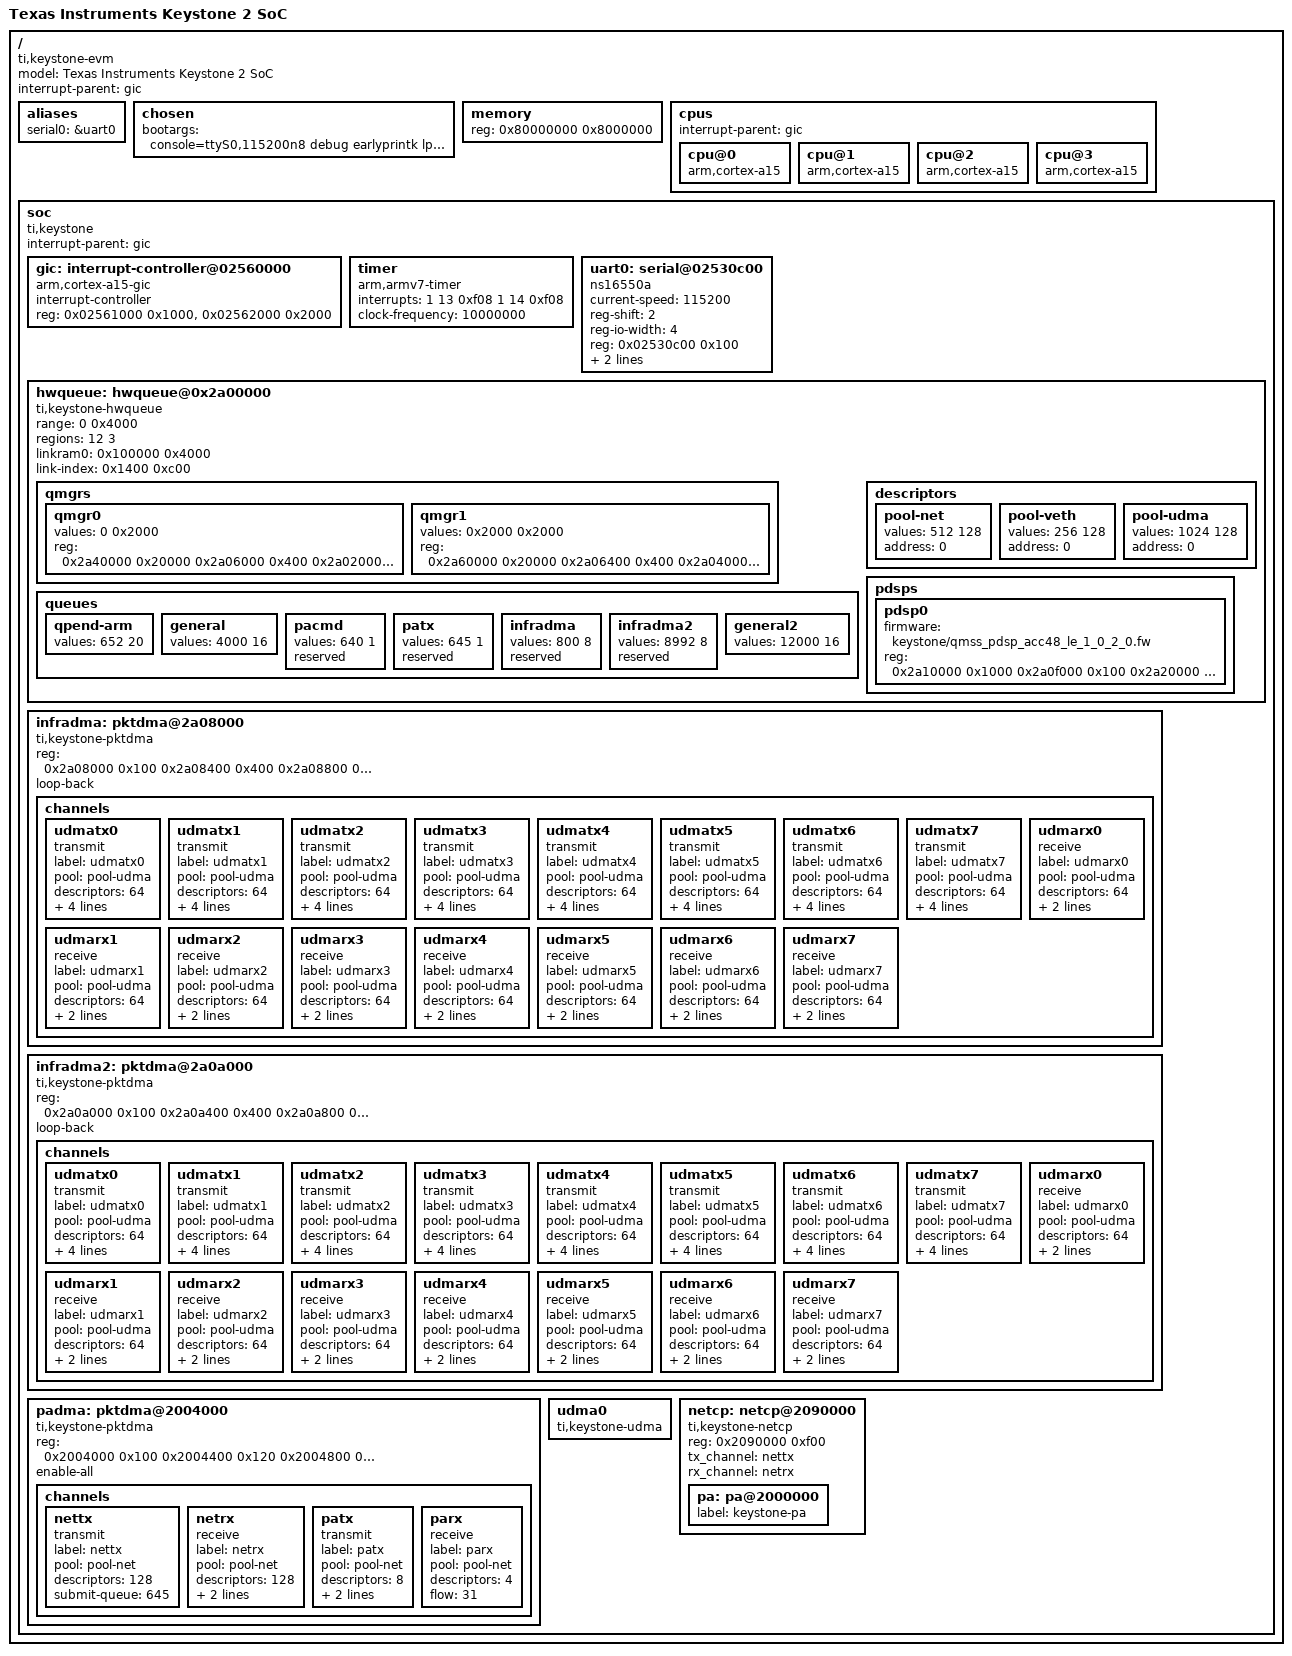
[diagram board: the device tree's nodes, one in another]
/dts-v1/;
/include/ "skeleton.dtsi"

/ {
	model = "Texas Instruments Keystone 2 SoC";
	compatible = "ti,keystone-evm";
	#address-cells = <1>;
	#size-cells = <1>;
	interrupt-parent = <&gic>;

	aliases {
		serial0	= &uart0;
	};

	chosen {
		bootargs = "console=ttyS0,115200n8 debug earlyprintk lpj=50000 rdinit=/bin/ash rw root=/dev/ram0 initrd=0x85000000,9M";
	};

	memory {
		reg = <0x80000000 0x8000000>;
	};

	cpus {
		interrupt-parent = <&gic>;

		cpu@0 {
			compatible = "arm,cortex-a15";

		};

		cpu@1 {
			compatible = "arm,cortex-a15";

		};

		cpu@2 {
			compatible = "arm,cortex-a15";

		};

		cpu@3 {
			compatible = "arm,cortex-a15";

		};

	};

	soc {
		#address-cells = <1>;
		#size-cells = <1>;
		ranges;
		compatible = "ti,keystone","simple-bus";
		interrupt-parent = <&gic>;

		gic:	interrupt-controller@02560000 {
			compatible = "arm,cortex-a15-gic";
			#interrupt-cells = <3>;
			#size-cells = <0>;
			#address-cells = <1>;
			interrupt-controller;
			reg = <0x02561000 0x1000>,
			      <0x02562000 0x2000>;
		};

		timer {
			compatible = "arm,armv7-timer";
			interrupts = <1 13 0xf08 1 14 0xf08>;
			clock-frequency = <10000000>; /* Freq in Hz - optional */
		};

		uart0:	serial@02530c00 {
			compatible      = "ns16550a";
			current-speed   = <115200>;
			reg-shift       = <2>;
			reg-io-width    = <4>;
			reg		= <0x02530c00 0x100>;
			clock-frequency = <48000000>;
			interrupts	= <0 277 0xf01>;
		};

		hwqueue: hwqueue@0x2a00000 {
			compatible = "ti,keystone-hwqueue";
			#address-cells = <1>;
			#size-cells = <1>;
			ranges;
			range		= <0 0x4000>;
			regions		= <12 3>;
			linkram0	= <0x100000 0x4000>;
			link-index	= <0x1400 0xc00>;
			qmgrs {
				#address-cells = <1>;
				#size-cells = <1>;
				ranges;
				qmgr0 {
					values = <0 0x2000>;		/* managed queues */
					reg = <0x2a40000 0x20000	/* 0 - peek	*/
			       		       0x2a06000 0x400		/* 1 - status	*/
			       		       0x2a02000 0x1000		/* 2 - config	*/
					       0x2a03000 0x1000		/* 3 - region	*/
					       0x2a80000 0x20000	/* 4 - push	*/
					       0x2a80000 0x20000>;	/* 5 - pop	*/
				};
				
				qmgr1 {
					values = <0x2000 0x2000>;	/* managed queues */
					reg = <0x2a60000 0x20000	/* 0 - peek	*/
			       		       0x2a06400 0x400		/* 1 - status	*/
			       		       0x2a04000 0x1000		/* 2 - config	*/
					       0x2a05000 0x1000		/* 3 - region	*/
					       0x2aa0000 0x20000	/* 4 - push	*/
					       0x2aa0000 0x20000>;	/* 5 - pop	*/
				};
				
			};	
			
			queues {
				qpend-arm {
					values = <652 20>;
					/*interrupts = <0 48 0xf01>;*/
				};
				general {
					values = <4000 16>;
				};
				pacmd {
					values = <640 1>;
					reserved;
				};
				patx {
					values = <645 1>;
					reserved;
				};
				infradma {
					values = <800 8>;
					reserved;
				};
				infradma2 {
					values = <8992 8>;
					reserved;
				};
				general2 {
					values = <12000 16>;
				};
			};
			descriptors {
				pool-net {
					values = <512 128>;	/* num_desc desc_size */
					address = <0>;		/* dynamic allocated pool */
				};
				pool-veth {
					values = <256 128>;	/* num_desc desc_size */
					address = <0>;		/* dynamic allocated pool */
				};
				pool-udma {
					values = <1024 128>;	/* num_desc desc_size */
					address = <0>;		/* dynamic allocated pool */
				};
			};
			pdsps {
				#address-cells = <1>;
				#size-cells = <1>;
				ranges;
				pdsp0 {
					firmware = "keystone/qmss_pdsp_acc48_le_1_0_2_0.fw";
					reg = <0x2a10000 0x1000    /* iram */
					       0x2a0f000 0x100     /* reg */
					       0x2a20000 0x4000>;  /* cmd */
				};
			};
		};

		infradma: pktdma@2a08000 {
			compatible = "ti,keystone-pktdma";
			reg = <0x2a08000 0x100		/* 0 - global  */
			       0x2a08400 0x400		/* 1 - txchan  */
			       0x2a08800 0x400		/* 2 - rxchan  */
			       0x2a08c00 0x400		/* 3 - txsched */
			       0x2a09000 0x400>;	/* 4 - rxflow  */
			loop-back;
			/* big-endian; */
			/* enable-all; */
			/* debug; */
			channels {
				udmatx0 {
					transmit;
					label		= "udmatx0";
					pool		= "pool-udma";
					descriptors	= <64>;
					submit-queue	= <800>;
					/* complete-queue = <xx>; */
					/* debug; */
					channel		= <0>;
					priority	= <1>;
					flowtag		= <0>;
				};
				udmatx1 {
					transmit;
					label		= "udmatx1";
					pool		= "pool-udma";
					descriptors	= <64>;
					submit-queue	= <801>;
					/* complete-queue = <xx>; */
					/* debug; */
					channel		= <1>;
					priority	= <1>;
					flowtag		= <1>;
				};
				udmatx2 {
					transmit;
					label		= "udmatx2";
					pool		= "pool-udma";
					descriptors	= <64>;
					submit-queue	= <802>;
					/* complete-queue = <xx>; */
					/* debug; */
					channel		= <2>;
					priority	= <1>;
					flowtag		= <2>;
				};
				udmatx3 {
					transmit;
					label		= "udmatx3";
					pool		= "pool-udma";
					descriptors	= <64>;
					submit-queue	= <803>;
					/* complete-queue = <xx>; */
					/* debug; */
					channel		= <3>;
					priority	= <1>;
					flowtag		= <3>;
				};
				udmatx4 {
					transmit;
					label		= "udmatx4";
					pool		= "pool-udma";
					descriptors	= <64>;
					submit-queue	= <804>;
					/* complete-queue = <xx>; */
					/* debug; */
					channel		= <4>;
					priority	= <1>;
					flowtag		= <4>;
				};
				udmatx5 {
					transmit;
					label		= "udmatx5";
					pool		= "pool-udma";
					descriptors	= <64>;
					submit-queue	= <805>;
					/* complete-queue = <xx>; */
					/* debug; */
					channel		= <5>;
					priority	= <1>;
					flowtag		= <5>;
				};
				udmatx6 {
					transmit;
					label		= "udmatx6";
					pool		= "pool-udma";
					descriptors	= <64>;
					submit-queue	= <806>;
					/* complete-queue = <xx>; */
					/* debug; */
					channel		= <6>;
					priority	= <1>;
					flowtag		= <6>;
				};
				udmatx7 {
					transmit;
					label		= "udmatx7";
					pool		= "pool-udma";
					descriptors	= <64>;
					submit-queue	= <807>;
					/* complete-queue = <xx>; */
					/* debug; */
					channel		= <7>;
					priority	= <1>;
					flowtag		= <7>;
				};
				udmarx0 {
					receive;
					label		= "udmarx0";
					pool		= "pool-udma";
					descriptors	= <64>;
					/* submit-queue   = <xx>; */
					/* complete-queue = <xx>; */
					/* debug; */
					channel		= <0>;
					flow		= <0>;
				};
				udmarx1 {
					receive;
					label		= "udmarx1";
					pool		= "pool-udma";
					descriptors	= <64>;
					/* submit-queue   = <xx>; */
					/* complete-queue = <xx>; */
					/* debug; */
					channel		= <1>;
					flow		= <1>;
				};
				udmarx2 {
					receive;
					label		= "udmarx2";
					pool		= "pool-udma";
					descriptors	= <64>;
					/* submit-queue   = <xx>; */
					/* complete-queue = <xx>; */
					/* debug; */
					channel		= <2>;
					flow		= <2>;
				};
				udmarx3 {
					receive;
					label		= "udmarx3";
					pool		= "pool-udma";
					descriptors	= <64>;
					/* submit-queue   = <xx>; */
					/* complete-queue = <xx>; */
					/* debug; */
					channel		= <3>;
					flow		= <3>;
				};
				udmarx4 {
					receive;
					label		= "udmarx4";
					pool		= "pool-udma";
					descriptors	= <64>;
					/* submit-queue   = <xx>; */
					/* complete-queue = <xx>; */
					/* debug; */
					channel		= <4>;
					flow		= <4>;
				};
				udmarx5 {
					receive;
					label		= "udmarx5";
					pool		= "pool-udma";
					descriptors	= <64>;
					/* submit-queue   = <xx>; */
					/* complete-queue = <xx>; */
					/* debug; */
					channel		= <5>;
					flow		= <5>;
				};
				udmarx6 {
					receive;
					label		= "udmarx6";
					pool		= "pool-udma";
					descriptors	= <64>;
					/* submit-queue   = <xx>; */
					/* complete-queue = <xx>; */
					/* debug; */
					channel		= <6>;
					flow		= <6>;
				};
				udmarx7 {
					receive;
					label		= "udmarx7";
					pool		= "pool-udma";
					descriptors	= <64>;
					/* submit-queue   = <xx>; */
					/* complete-queue = <xx>; */
					/* debug; */
					channel		= <7>;
					flow		= <7>;
				};
			};
		};

		infradma2: pktdma@2a0a000 {
			compatible = "ti,keystone-pktdma";
			reg = <0x2a0a000 0x100		/* 0 - global  */
			       0x2a0a400 0x400		/* 1 - txchan  */
			       0x2a0a800 0x400		/* 2 - rxchan  */
			       0x2a0ac00 0x400		/* 3 - txsched */
			       0x2a0b000 0x400>;	/* 4 - rxflow  */
			loop-back;
			/* big-endian; */
			/* enable-all; */
			/* debug; */
			channels {
				udmatx0 {
					transmit;
					label		= "udmatx0";
					pool		= "pool-udma";
					descriptors	= <64>;
					submit-queue	= <8992>;
					/* complete-queue = <xx>; */
					/* debug; */
					channel		= <0>;
					priority	= <1>;
					flowtag		= <0>;
				};
				udmatx1 {
					transmit;
					label		= "udmatx1";
					pool		= "pool-udma";
					descriptors	= <64>;
					submit-queue	= <8993>;
					/* complete-queue = <xx>; */
					/* debug; */
					channel		= <1>;
					priority	= <1>;
					flowtag		= <1>;
				};
				udmatx2 {
					transmit;
					label		= "udmatx2";
					pool		= "pool-udma";
					descriptors	= <64>;
					submit-queue	= <8994>;
					/* complete-queue = <xx>; */
					/* debug; */
					channel		= <2>;
					priority	= <1>;
					flowtag		= <2>;
				};
				udmatx3 {
					transmit;
					label		= "udmatx3";
					pool		= "pool-udma";
					descriptors	= <64>;
					submit-queue	= <8995>;
					/* complete-queue = <xx>; */
					/* debug; */
					channel		= <3>;
					priority	= <1>;
					flowtag		= <3>;
				};
				udmatx4 {
					transmit;
					label		= "udmatx4";
					pool		= "pool-udma";
					descriptors	= <64>;
					submit-queue	= <8996>;
					/* complete-queue = <xx>; */
					/* debug; */
					channel		= <4>;
					priority	= <1>;
					flowtag		= <4>;
				};
				udmatx5 {
					transmit;
					label		= "udmatx5";
					pool		= "pool-udma";
					descriptors	= <64>;
					submit-queue	= <8997>;
					/* complete-queue = <xx>; */
					/* debug; */
					channel		= <5>;
					priority	= <1>;
					flowtag		= <5>;
				};
				udmatx6 {
					transmit;
					label		= "udmatx6";
					pool		= "pool-udma";
					descriptors	= <64>;
					submit-queue	= <8998>;
					/* complete-queue = <xx>; */
					/* debug; */
					channel		= <6>;
					priority	= <1>;
					flowtag		= <6>;
				};
				udmatx7 {
					transmit;
					label		= "udmatx7";
					pool		= "pool-udma";
					descriptors	= <64>;
					submit-queue	= <8999>;
					/* complete-queue = <xx>; */
					/* debug; */
					channel		= <7>;
					priority	= <1>;
					flowtag		= <7>;
				};
				udmarx0 {
					receive;
					label		= "udmarx0";
					pool		= "pool-udma";
					descriptors	= <64>;
					/* submit-queue   = <xx>; */
					/* complete-queue = <xx>; */
					/* debug; */
					channel		= <0>;
					flow		= <0>;
				};
				udmarx1 {
					receive;
					label		= "udmarx1";
					pool		= "pool-udma";
					descriptors	= <64>;
					/* submit-queue   = <xx>; */
					/* complete-queue = <xx>; */
					/* debug; */
					channel		= <1>;
					flow		= <1>;
				};
				udmarx2 {
					receive;
					label		= "udmarx2";
					pool		= "pool-udma";
					descriptors	= <64>;
					/* submit-queue   = <xx>; */
					/* complete-queue = <xx>; */
					/* debug; */
					channel		= <2>;
					flow		= <2>;
				};
				udmarx3 {
					receive;
					label		= "udmarx3";
					pool		= "pool-udma";
					descriptors	= <64>;
					/* submit-queue   = <xx>; */
					/* complete-queue = <xx>; */
					/* debug; */
					channel		= <3>;
					flow		= <3>;
				};
				udmarx4 {
					receive;
					label		= "udmarx4";
					pool		= "pool-udma";
					descriptors	= <64>;
					/* submit-queue   = <xx>; */
					/* complete-queue = <xx>; */
					/* debug; */
					channel		= <4>;
					flow		= <4>;
				};
				udmarx5 {
					receive;
					label		= "udmarx5";
					pool		= "pool-udma";
					descriptors	= <64>;
					/* submit-queue   = <xx>; */
					/* complete-queue = <xx>; */
					/* debug; */
					channel		= <5>;
					flow		= <5>;
				};
				udmarx6 {
					receive;
					label		= "udmarx6";
					pool		= "pool-udma";
					descriptors	= <64>;
					/* submit-queue   = <xx>; */
					/* complete-queue = <xx>; */
					/* debug; */
					channel		= <6>;
					flow		= <6>;
				};
				udmarx7 {
					receive;
					label		= "udmarx7";
					pool		= "pool-udma";
					descriptors	= <64>;
					/* submit-queue   = <xx>; */
					/* complete-queue = <xx>; */
					/* debug; */
					channel		= <7>;
					flow		= <7>;
				};
			};
		};

		padma: pktdma@2004000 {
			compatible = "ti,keystone-pktdma";
			reg = <0x2004000 0x100		/* 0 - global  */
			       0x2004400 0x120		/* 1 - txchan  */
			       0x2004800 0x300		/* 2 - rxchan  */
			       0x2004c00 0x120		/* 3 - txsched */
			       0x2005000 0x400>;	/* 4 - rxflow  */
			/* loop-back;  */
			/* bigendian; */
			enable-all;
			/* debug; */
			channels {
				nettx {
					transmit;
					label		= "nettx";
					pool		= "pool-net";
					descriptors	= <128>;
					submit-queue	= <645>;
					/* complete-queue = <xx>; */
					/* debug; */
					/* channel = <0>; */
					/* priority = <1>; */
				};
				netrx {
					receive;
					label		= "netrx";
					pool		= "pool-net";
					descriptors	= <128>;
					/* submit-queue   = <xx>; */
					complete-queue = <657>;
					/* debug; */
					/* channel = <0>; */
					flow		= <30>;
				};
				patx {
					transmit;
					label		= "patx";
					pool		= "pool-net";
					descriptors	= <8>;
					submit-queue	= <640>;
					/* complete-queue = <xx>; */
					/* debug; */
					/* channel = <xx>; */
					/* priority = <1>; */
					queues		= <640 4013>;
				};
				parx {
					receive;
					label		= "parx";
					pool		= "pool-net";
					descriptors	= <4>;
					/* submit-queue   = <xx>; */
					/* complete-queue = <xx>; */
					/* debug; */
					/* channel = <0>; */
					flow		= <31>;
				};
			};
		};

		udma0 {
			compatible = "ti,keystone-udma";
		};

		netcp: netcp@2090000 {
			reg = <0x2090000 0xf00>;
			compatible = "ti,keystone-netcp";

			tx_channel = "nettx";
			rx_channel = "netrx";
			pa: pa@2000000 {
				label = "keystone-pa";
			};

		};
	};
};

